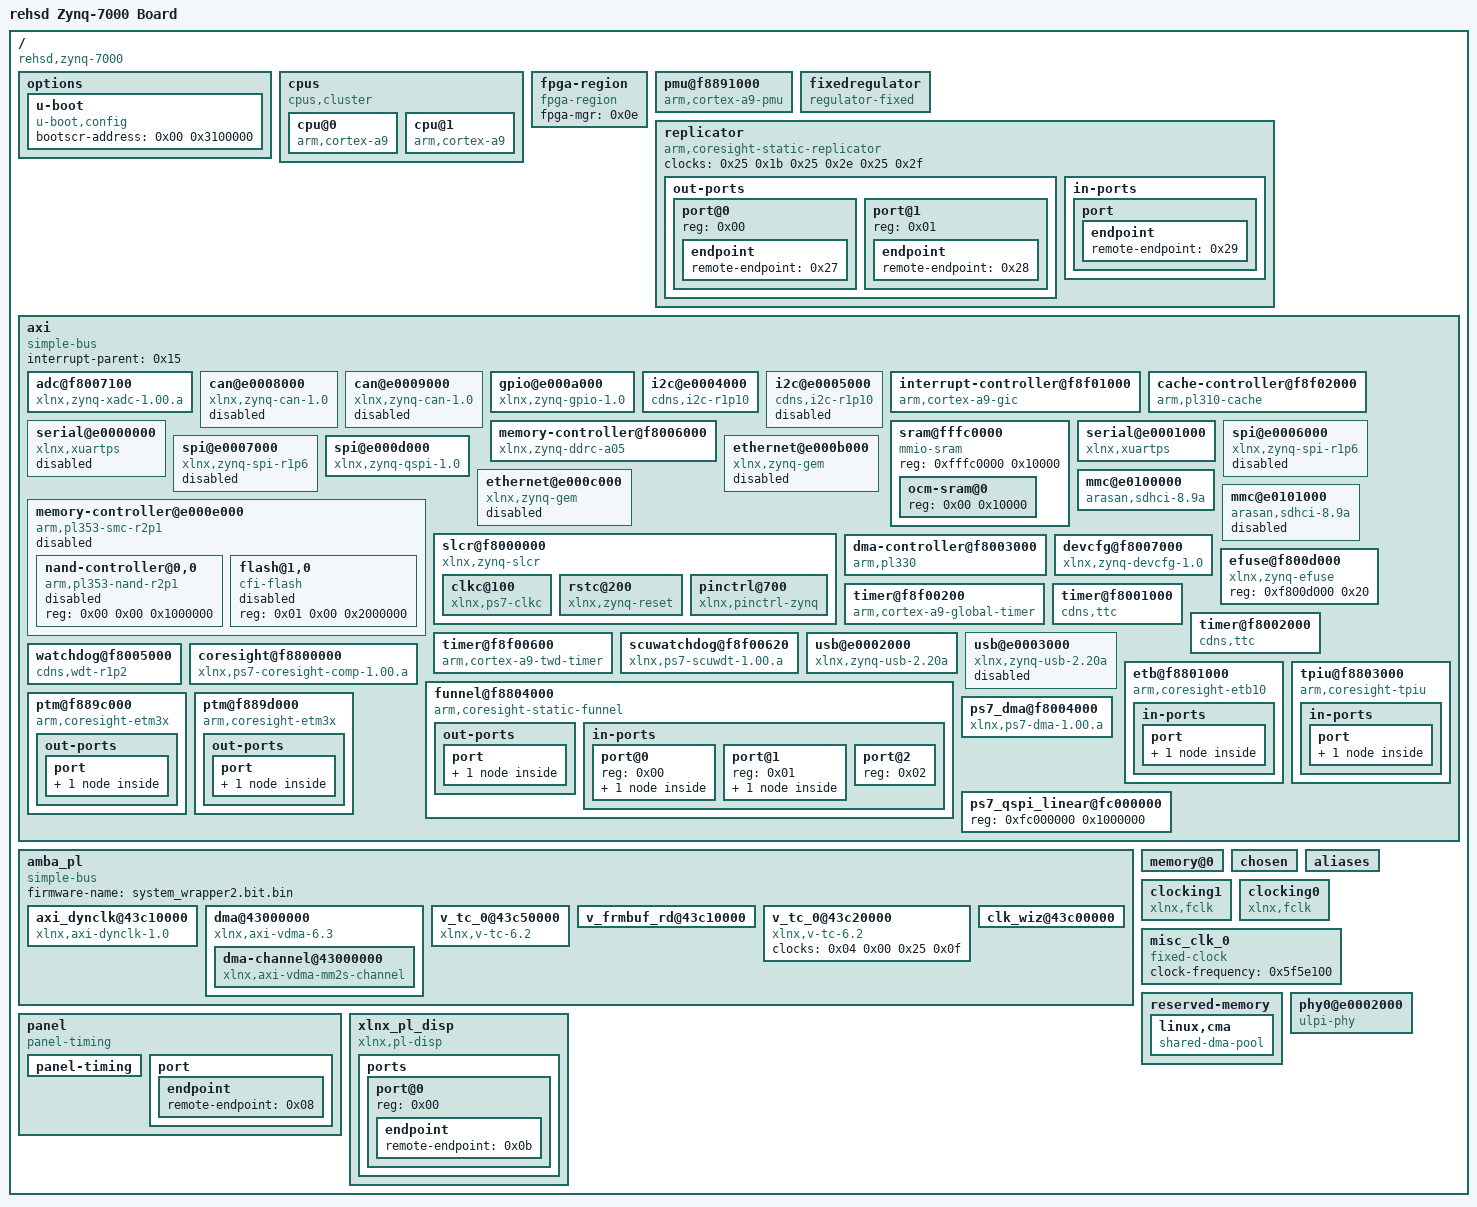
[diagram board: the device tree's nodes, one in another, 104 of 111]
/dts-v1/;

/ {
	#address-cells = <0x01>;
	#size-cells = <0x01>;
	compatible = "rehsd,zynq-7000\0xlnx,zynq-7000";
	model = "rehsd Zynq-7000 Board";
	device_id = "7z010";
	slrcount = <0x01>;
	family = "Zynq";
	speed_grade = "1";

	options {

		u-boot {
			compatible = "u-boot,config";
			bootscr-address = <0x00 0x3100000>;
		};
	};

	cpus {
		phandle = <0x34>;
		#address-cells = <0x01>;
		#size-cells = <0x00>;
		compatible = "cpus,cluster";
		#ranges-address-cells = <0x01>;
		#ranges-size-cells = <0x01>;

		cpu@0 {
			phandle = <0x2f>;
			compatible = "arm,cortex-a9";
			device_type = "cpu";
			reg = <0x00>;
			clocks = <0x25 0x03>;
			clock-latency = <0x3e8>;
			cpu0-supply = <0x26>;
			operating-points = <0xa2c2b 0xf4240 0x51616 0xf4240>;
			xlnx,i-cache-size = <0x8000>;
			xlnx,d-cache-line-size = <0x14>;
			xlnx,i-cache-line-size = <0x14>;
			xlnx,cpu-1x-clk-freq-hz = <0x69f6bcb>;
			xlnx,ip-name = "ps7_cortexa9";
			xlnx,d-cache-size = <0x8000>;
			xlnx,num-cores = <0x02>;
			xlnx,cpu-clk-freq-hz = <0x27bc86bf>;
			bus-handle = <0x01>;
		};

		cpu@1 {
			phandle = <0x31>;
			compatible = "arm,cortex-a9";
			device_type = "cpu";
			reg = <0x01>;
			clocks = <0x25 0x03>;
			xlnx,i-cache-size = <0x8000>;
			xlnx,d-cache-line-size = <0x14>;
			xlnx,i-cache-line-size = <0x14>;
			xlnx,cpu-1x-clk-freq-hz = <0x69f6bcb>;
			xlnx,ip-name = "ps7_cortexa9";
			xlnx,d-cache-size = <0x8000>;
			xlnx,cpu-clk-freq-hz = <0x27bc86bf>;
			bus-handle = <0x01>;
		};
	};

	fpga-region {
		phandle = <0x35>;
		compatible = "fpga-region";
		fpga-mgr = <0x0e>;
		#address-cells = <0x01>;
		#size-cells = <0x01>;
		ranges;
	};

	pmu@f8891000 {
		compatible = "arm,cortex-a9-pmu";
		interrupts = <0x00 0x05 0x04 0x00 0x06 0x04>;
		interrupt-parent = <0x15>;
		reg = <0xf8891000 0x1000 0xf8893000 0x1000>;
	};

	fixedregulator {
		phandle = <0x26>;
		compatible = "regulator-fixed";
		regulator-name = "VCCPINT";
		regulator-min-microvolt = <0xf4240>;
		regulator-max-microvolt = <0xf4240>;
		regulator-boot-on;
		regulator-always-on;
	};

	replicator {
		compatible = "arm,coresight-static-replicator";
		clocks = <0x25 0x1b 0x25 0x2e 0x25 0x2f>;
		clock-names = "apb_pclk\0dbg_trc\0dbg_apb";

		out-ports {
			#address-cells = <0x01>;
			#size-cells = <0x00>;

			port@0 {
				reg = <0x00>;

				endpoint {
					phandle = <0x2b>;
					remote-endpoint = <0x27>;
				};
			};

			port@1 {
				reg = <0x01>;

				endpoint {
					phandle = <0x2a>;
					remote-endpoint = <0x28>;
				};
			};
		};

		in-ports {

			port {

				endpoint {
					phandle = <0x2c>;
					remote-endpoint = <0x29>;
				};
			};
		};
	};

	axi {
		phandle = <0x01>;
		bootph-all;
		compatible = "simple-bus";
		#address-cells = <0x01>;
		#size-cells = <0x01>;
		interrupt-parent = <0x15>;
		ranges;

		adc@f8007100 {
			phandle = <0x24>;
			compatible = "xlnx,zynq-xadc-1.00.a";
			reg = <0xf8007100 0x20>;
			interrupts = <0x00 0x07 0x04>;
			interrupt-parent = <0x15>;
			clocks = <0x25 0x0c>;
			status = "okay";
			xlnx,ip-name = "ps7_xadc";
		};

		can@e0008000 {
			phandle = <0x36>;
			compatible = "xlnx,zynq-can-1.0";
			status = "disabled";
			clocks = <0x25 0x13 0x25 0x24>;
			clock-names = "can_clk\0pclk";
			reg = <0xe0008000 0x1000>;
			interrupts = <0x00 0x1c 0x04>;
			interrupt-parent = <0x15>;
			tx-fifo-depth = <0x40>;
			rx-fifo-depth = <0x40>;
		};

		can@e0009000 {
			phandle = <0x37>;
			compatible = "xlnx,zynq-can-1.0";
			status = "disabled";
			clocks = <0x25 0x14 0x25 0x25>;
			clock-names = "can_clk\0pclk";
			reg = <0xe0009000 0x1000>;
			interrupts = <0x00 0x33 0x04>;
			interrupt-parent = <0x15>;
			tx-fifo-depth = <0x40>;
			rx-fifo-depth = <0x40>;
		};

		gpio@e000a000 {
			phandle = <0x12>;
			compatible = "xlnx,zynq-gpio-1.0";
			#gpio-cells = <0x02>;
			clocks = <0x25 0x2a>;
			gpio-controller;
			interrupt-controller;
			#interrupt-cells = <0x02>;
			interrupt-parent = <0x15>;
			interrupts = <0x00 0x14 0x04>;
			reg = <0xe000a000 0x1000>;
			xlnx,mio-gpio-mask = <0x5600>;
			status = "okay";
			gpio-mask-high = <0x00>;
			xlnx,emio-gpio-width = <0x40>;
			xlnx,ip-name = "ps7_gpio";
			gpio-mask-low = <0x5600>;
			emio-gpio-width = <0x40>;
		};

		i2c@e0004000 {
			phandle = <0x14>;
			compatible = "cdns,i2c-r1p10";
			status = "okay";
			clocks = <0x25 0x26>;
			interrupt-parent = <0x15>;
			interrupts = <0x00 0x19 0x04>;
			clock-frequency = <0x61a80>;
			reg = <0xe0004000 0x1000>;
			#address-cells = <0x01>;
			#size-cells = <0x00>;
			xlnx,has-interrupt = <0x00>;
			xlnx,clock-freq = <0x69f6bcb>;
			xlnx,i2c-clk-freq-hz = <0x69f6bcb>;
			xlnx,ip-name = "ps7_i2c";
		};

		i2c@e0005000 {
			phandle = <0x38>;
			compatible = "cdns,i2c-r1p10";
			status = "disabled";
			clocks = <0x25 0x27>;
			interrupt-parent = <0x15>;
			interrupts = <0x00 0x30 0x04>;
			clock-frequency = <0x61a80>;
			reg = <0xe0005000 0x1000>;
			#address-cells = <0x01>;
			#size-cells = <0x00>;
		};

		interrupt-controller@f8f01000 {
			phandle = <0x15>;
			compatible = "arm,cortex-a9-gic";
			#interrupt-cells = <0x03>;
			interrupt-controller;
			reg = <0xf8f01000 0x1000 0xf8f00100 0x100>;
			status = "okay";
			xlnx,irq-f2p-mode = "DIRECT";
			xlnx,ip-name = "ps7_intc_dist";
		};

		cache-controller@f8f02000 {
			phandle = <0x17>;
			compatible = "arm,pl310-cache";
			reg = <0xf8f02000 0x1000>;
			interrupts = <0x00 0x02 0x04>;
			arm,data-latency = <0x03 0x02 0x02>;
			arm,tag-latency = <0x02 0x02 0x02>;
			cache-unified;
			cache-level = <0x02>;
			status = "okay";
			xlnx,ip-name = "ps7_pl310";
		};

		memory-controller@f8006000 {
			phandle = <0x0d>;
			compatible = "xlnx,zynq-ddrc-a05";
			reg = <0xf8006000 0x1000>;
			status = "okay";
			xlnx,ddr-clk-freq-hz = <0x1fca057e>;
			xlnx,ip-name = "ps7_ddrc";
			xlnx,has-ecc = <0x00>;
		};

		sram@fffc0000 {
			phandle = <0x39>;
			compatible = "mmio-sram";
			reg = <0xfffc0000 0x10000>;
			#address-cells = <0x01>;
			#size-cells = <0x01>;
			ranges = <0x00 0xfffc0000 0x10000>;

			ocm-sram@0 {
				reg = <0x00 0x10000>;
			};
		};

		serial@e0000000 {
			phandle = <0x3a>;
			compatible = "xlnx,xuartps\0cdns,uart-r1p8";
			status = "disabled";
			clocks = <0x25 0x17 0x25 0x28>;
			clock-names = "uart_clk\0pclk";
			reg = <0xe0000000 0x1000>;
			interrupts = <0x00 0x1b 0x04>;
			interrupt-parent = <0x15>;
		};

		serial@e0001000 {
			phandle = <0x22>;
			compatible = "xlnx,xuartps\0cdns,uart-r1p8";
			status = "okay";
			clocks = <0x25 0x18 0x25 0x29>;
			clock-names = "uart_clk\0pclk";
			reg = <0xe0001000 0x1000>;
			interrupts = <0x00 0x32 0x04>;
			interrupt-parent = <0x15>;
			xlnx,clock-freq = <0x5f5e100>;
			xlnx,has-modem = <0x00>;
			xlnx,ip-name = "ps7_uart";
			cts-override;
			port-number = <0x00>;
			xlnx,uart-clk-freq-hz = <0x5f5e100>;
		};

		spi@e0006000 {
			phandle = <0x3b>;
			compatible = "xlnx,zynq-spi-r1p6";
			reg = <0xe0006000 0x1000>;
			status = "disabled";
			interrupt-parent = <0x15>;
			interrupts = <0x00 0x1a 0x04>;
			clocks = <0x25 0x19 0x25 0x22>;
			clock-names = "ref_clk\0pclk";
			#address-cells = <0x01>;
			#size-cells = <0x00>;
		};

		spi@e0007000 {
			phandle = <0x3c>;
			compatible = "xlnx,zynq-spi-r1p6";
			reg = <0xe0007000 0x1000>;
			status = "disabled";
			interrupt-parent = <0x15>;
			interrupts = <0x00 0x31 0x04>;
			clocks = <0x25 0x1a 0x25 0x23>;
			clock-names = "ref_clk\0pclk";
			#address-cells = <0x01>;
			#size-cells = <0x00>;
		};

		spi@e000d000 {
			phandle = <0x1a>;
			compatible = "xlnx,zynq-qspi-1.0";
			reg = <0xe000d000 0x1000>;
			interrupt-parent = <0x15>;
			interrupts = <0x00 0x13 0x04>;
			clocks = <0x25 0x0a 0x25 0x2b>;
			clock-names = "ref_clk\0pclk";
			status = "okay";
			#address-cells = <0x01>;
			#size-cells = <0x00>;
			xlnx,qspi-fbclk = <0x00>;
			num-cs = <0x01>;
			xlnx,qspi-clk-freq-hz = <0xbebc200>;
			xlnx,bus-width = <0x02>;
			xlnx,ip-name = "ps7_qspi";
			spi-rx-bus-width = <0x04>;
			xlnx,connection-mode = <0x00>;
			spi-tx-bus-width = <0x04>;
			xlnx,clock-freq = <0xbebc200>;
			xlnx,fb-clk = <0x00>;
			xlnx,qspi-mode = <0x00>;
			xlnx,qspi-bus-width = <0x02>;
			is-dual = <0x00>;
		};

		ethernet@e000b000 {
			phandle = <0x3d>;
			compatible = "xlnx,zynq-gem\0cdns,gem";
			reg = <0xe000b000 0x1000>;
			status = "disabled";
			interrupts = <0x00 0x16 0x04>;
			interrupt-parent = <0x15>;
			clocks = <0x25 0x1e 0x25 0x1e 0x25 0x0d>;
			clock-names = "pclk\0hclk\0tx_clk";
			#address-cells = <0x01>;
			#size-cells = <0x00>;
		};

		ethernet@e000c000 {
			phandle = <0x3e>;
			compatible = "xlnx,zynq-gem\0cdns,gem";
			reg = <0xe000c000 0x1000>;
			status = "disabled";
			interrupts = <0x00 0x2d 0x04>;
			interrupt-parent = <0x15>;
			clocks = <0x25 0x1f 0x25 0x1f 0x25 0x0e>;
			clock-names = "pclk\0hclk\0tx_clk";
			#address-cells = <0x01>;
			#size-cells = <0x00>;
		};

		memory-controller@e000e000 {
			phandle = <0x3f>;
			compatible = "arm,pl353-smc-r2p1\0arm,primecell";
			reg = <0xe000e000 0x1000>;
			status = "disabled";
			clock-names = "memclk\0apb_pclk";
			clocks = <0x25 0x0b 0x25 0x2c>;
			ranges = <0x00 0x00 0xe1000000 0x1000000 0x01 0x00 0xe2000000 0x2000000 0x02 0x00 0xe4000000 0x2000000>;
			#address-cells = <0x02>;
			#size-cells = <0x01>;
			interrupt-parent = <0x15>;
			interrupts = <0x00 0x12 0x04>;

			nand-controller@0,0 {
				phandle = <0x40>;
				compatible = "arm,pl353-nand-r2p1";
				reg = <0x00 0x00 0x1000000>;
				status = "disabled";
			};

			flash@1,0 {
				phandle = <0x41>;
				status = "disabled";
				compatible = "cfi-flash";
				reg = <0x01 0x00 0x2000000>;
			};
		};

		mmc@e0100000 {
			phandle = <0x1f>;
			compatible = "arasan,sdhci-8.9a";
			status = "okay";
			clock-names = "clk_xin\0clk_ahb";
			clocks = <0x25 0x15 0x25 0x20>;
			interrupt-parent = <0x15>;
			interrupts = <0x00 0x18 0x04>;
			reg = <0xe0100000 0x1000>;
			xlnx,has-power = <0x00>;
			xlnx,ip-name = "ps7_sdio";
			xlnx,sdio-clk-freq-hz = <0x5f5e100>;
			xlnx,has-wp = <0x00>;
			xlnx,has-cd = <0x00>;
			u-boot,dm-pre-reloc;
		};

		mmc@e0101000 {
			phandle = <0x42>;
			compatible = "arasan,sdhci-8.9a";
			status = "disabled";
			clock-names = "clk_xin\0clk_ahb";
			clocks = <0x25 0x16 0x25 0x21>;
			interrupt-parent = <0x15>;
			interrupts = <0x00 0x2f 0x04>;
			reg = <0xe0101000 0x1000>;
		};

		slcr@f8000000 {
			phandle = <0x20>;
			bootph-all;
			#address-cells = <0x01>;
			#size-cells = <0x01>;
			compatible = "xlnx,zynq-slcr\0syscon\0simple-mfd";
			reg = <0xf8000000 0x1000>;
			ranges;
			status = "okay";
			xlnx,ip-name = "ps7_slcr";

			clkc@100 {
				phandle = <0x25>;
				bootph-all;
				#clock-cells = <0x01>;
				compatible = "xlnx,ps7-clkc";
				fclk-enable = <0x01>;
				clock-output-names = "armpll\0ddrpll\0iopll\0cpu_6or4x\0cpu_3or2x\0cpu_2x\0cpu_1x\0ddr2x\0ddr3x\0dci\0lqspi\0smc\0pcap\0gem0\0gem1\0fclk0\0fclk1\0fclk2\0fclk3\0can0\0can1\0sdio0\0sdio1\0uart0\0uart1\0spi0\0spi1\0dma\0usb0_aper\0usb1_aper\0gem0_aper\0gem1_aper\0sdio0_aper\0sdio1_aper\0spi0_aper\0spi1_aper\0can0_aper\0can1_aper\0i2c0_aper\0i2c1_aper\0uart0_aper\0uart1_aper\0gpio_aper\0lqspi_aper\0smc_aper\0swdt\0dbg_trc\0dbg_apb";
				reg = <0x100 0x100>;
				ps-clk-frequency = <0x1fca055>;
			};

			rstc@200 {
				phandle = <0x43>;
				compatible = "xlnx,zynq-reset";
				reg = <0x200 0x48>;
				#reset-cells = <0x01>;
				syscon = <0x20>;
			};

			pinctrl@700 {
				phandle = <0x44>;
				compatible = "xlnx,pinctrl-zynq";
				reg = <0x700 0x200>;
				syscon = <0x20>;
			};
		};

		dma-controller@f8003000 {
			phandle = <0x10>;
			compatible = "arm,pl330\0arm,primecell";
			reg = <0xf8003000 0x1000>;
			interrupt-parent = <0x15>;
			interrupts = <0x00 0x0d 0x04 0x00 0x0e 0x04 0x00 0x0f 0x04 0x00 0x10 0x04 0x00 0x11 0x04 0x00 0x28 0x04 0x00 0x29 0x04 0x00 0x2a 0x04 0x00 0x2b 0x04>;
			#dma-cells = <0x01>;
			clocks = <0x25 0x1b>;
			clock-names = "apb_pclk";
			status = "okay";
			xlnx,ip-name = "ps7_dma";
			xlnx,is-secure;
		};

		devcfg@f8007000 {
			phandle = <0x0e>;
			compatible = "xlnx,zynq-devcfg-1.0";
			reg = <0xf8007000 0x100>;
			interrupt-parent = <0x15>;
			interrupts = <0x00 0x08 0x04>;
			clocks = <0x25 0x0c 0x25 0x0f 0x25 0x10 0x25 0x11 0x25 0x12>;
			clock-names = "ref_clk\0fclk0\0fclk1\0fclk2\0fclk3";
			syscon = <0x20>;
			status = "okay";
			xlnx,ip-name = "ps7_dev_cfg";
		};

		efuse@f800d000 {
			phandle = <0x45>;
			compatible = "xlnx,zynq-efuse";
			reg = <0xf800d000 0x20>;
		};

		timer@f8f00200 {
			phandle = <0x11>;
			compatible = "arm,cortex-a9-global-timer";
			reg = <0xf8f00200 0x20>;
			interrupts = <0x01 0x0b 0x301>;
			interrupt-parent = <0x15>;
			clocks = <0x25 0x04>;
			status = "okay";
			xlnx,ip-name = "ps7_globaltimer";
		};

		timer@f8001000 {
			phandle = <0x21>;
			interrupt-parent = <0x15>;
			interrupts = <0x00 0x0a 0x04 0x00 0x0b 0x04 0x00 0x0c 0x04>;
			compatible = "cdns,ttc";
			clocks = <0x25 0x06>;
			reg = <0xf8001000 0x1000>;
			xlnx,ttc-clk2-freq-hz = <0x69f6bcb>;
			xlnx,ttc-clk1-clksrc = <0x00>;
			status = "okay";
			xlnx,clock-freq = <0x69f6bcb>;
			xlnx,ttc-clk2-clksrc = <0x00>;
			xlnx,ip-name = "ps7_ttc";
			xlnx,ttc-clk0-freq-hz = <0x69f6bcb>;
			xlnx,ttc-clk1-freq-hz = <0x69f6bcb>;
			xlnx,ttc-clk0-clksrc = <0x00>;
		};

		timer@f8002000 {
			phandle = <0x46>;
			interrupt-parent = <0x15>;
			interrupts = <0x00 0x25 0x04 0x00 0x26 0x04 0x00 0x27 0x04>;
			compatible = "cdns,ttc";
			clocks = <0x25 0x06>;
			reg = <0xf8002000 0x1000>;
		};

		timer@f8f00600 {
			phandle = <0x1d>;
			bootph-all;
			interrupt-parent = <0x15>;
			interrupts = <0x01 0x0d 0x301>;
			compatible = "arm,cortex-a9-twd-timer";
			reg = <0xf8f00600 0x20>;
			clocks = <0x25 0x04>;
			status = "okay";
			xlnx,ip-name = "ps7_scutimer";
		};

		scuwatchdog@f8f00620 {
			phandle = <0x1e>;
			interrupt-parent = <0x15>;
			interrupts = <0x01 0x0e 0x04>;
			compatible = "xlnx,ps7-scuwdt-1.00.a";
			reg = <0xf8f00620 0xe0>;
			status = "okay";
			xlnx,ip-name = "ps7_scuwdt";
		};

		usb@e0002000 {
			phandle = <0x23>;
			compatible = "xlnx,zynq-usb-2.20a\0chipidea,usb2";
			status = "okay";
			clocks = <0x25 0x1c>;
			interrupt-parent = <0x15>;
			interrupts = <0x00 0x15 0x04>;
			reg = <0xe0002000 0x1000>;
			phy_type = "ulpi";
			xlnx,ip-name = "ps7_usb";
			xlnx,enable-superspeed = <0x00>;
			dr_mode = "otg";
			usb-phy = <0x03>;
		};

		usb@e0003000 {
			phandle = <0x47>;
			compatible = "xlnx,zynq-usb-2.20a\0chipidea,usb2";
			status = "disabled";
			clocks = <0x25 0x1d>;
			interrupt-parent = <0x15>;
			interrupts = <0x00 0x2c 0x04>;
			reg = <0xe0003000 0x1000>;
			phy_type = "ulpi";
		};

		watchdog@f8005000 {
			phandle = <0x48>;
			clocks = <0x25 0x2d>;
			compatible = "cdns,wdt-r1p2";
			interrupt-parent = <0x15>;
			interrupts = <0x00 0x09 0x01>;
			reg = <0xf8005000 0x1000>;
			timeout-sec = <0x0a>;
		};

		coresight@f8800000 {
			phandle = <0x0c>;
			compatible = "xlnx,ps7-coresight-comp-1.00.a";
			status = "okay";
			reg = <0xf8800000 0x100000>;
			xlnx,ip-name = "ps7_coresight_comp";
		};

		etb@f8801000 {
			compatible = "arm,coresight-etb10\0arm,primecell";
			reg = <0xf8801000 0x1000>;
			clocks = <0x25 0x1b 0x25 0x2e 0x25 0x2f>;
			clock-names = "apb_pclk\0dbg_trc\0dbg_apb";

			in-ports {

				port {

					endpoint {
						phandle = <0x28>;
						remote-endpoint = <0x2a>;
					};
				};
			};
		};

		tpiu@f8803000 {
			compatible = "arm,coresight-tpiu\0arm,primecell";
			reg = <0xf8803000 0x1000>;
			clocks = <0x25 0x1b 0x25 0x2e 0x25 0x2f>;
			clock-names = "apb_pclk\0dbg_trc\0dbg_apb";

			in-ports {

				port {

					endpoint {
						phandle = <0x27>;
						remote-endpoint = <0x2b>;
					};
				};
			};
		};

		funnel@f8804000 {
			compatible = "arm,coresight-static-funnel\0arm,primecell";
			reg = <0xf8804000 0x1000>;
			clocks = <0x25 0x1b 0x25 0x2e 0x25 0x2f>;
			clock-names = "apb_pclk\0dbg_trc\0dbg_apb";

			out-ports {

				port {

					endpoint {
						phandle = <0x29>;
						remote-endpoint = <0x2c>;
					};
				};
			};

			in-ports {
				#address-cells = <0x01>;
				#size-cells = <0x00>;

				port@0 {
					reg = <0x00>;

					endpoint {
						phandle = <0x30>;
						remote-endpoint = <0x2d>;
					};
				};

				port@1 {
					reg = <0x01>;

					endpoint {
						phandle = <0x32>;
						remote-endpoint = <0x2e>;
					};
				};

				port@2 {
					reg = <0x02>;
				};
			};
		};

		ptm@f889c000 {
			compatible = "arm,coresight-etm3x\0arm,primecell";
			reg = <0xf889c000 0x1000>;
			clocks = <0x25 0x1b 0x25 0x2e 0x25 0x2f>;
			clock-names = "apb_pclk\0dbg_trc\0dbg_apb";
			cpu = <0x2f>;

			out-ports {

				port {

					endpoint {
						phandle = <0x2d>;
						remote-endpoint = <0x30>;
					};
				};
			};
		};

		ptm@f889d000 {
			compatible = "arm,coresight-etm3x\0arm,primecell";
			reg = <0xf889d000 0x1000>;
			clocks = <0x25 0x1b 0x25 0x2e 0x25 0x2f>;
			clock-names = "apb_pclk\0dbg_trc\0dbg_apb";
			cpu = <0x31>;

			out-ports {

				port {

					endpoint {
						phandle = <0x2e>;
						remote-endpoint = <0x32>;
					};
				};
			};
		};

		ps7_dma@f8004000 {
			phandle = <0x0f>;
			compatible = "xlnx,ps7-dma-1.00.a";
			status = "okay";
			xlnx,ip-name = "ps7_dma";
			xlnx,is-secure;
			reg = <0xf8004000 0x1000>;
		};

		ps7_qspi_linear@fc000000 {
			phandle = <0x4e>;
			reg = <0xfc000000 0x1000000>;
		};
	};

	amba_pl {
		phandle = <0x4f>;
		ranges;
		compatible = "simple-bus";
		#address-cells = <0x01>;
		#size-cells = <0x01>;
		firmware-name = "system_wrapper2.bit.bin";

		axi_dynclk@43c10000 {
			phandle = <0x06>;
			xlnx,s00-axi-data-width = <0x20>;
			compatible = "xlnx,axi-dynclk-1.0";
			status = "okay";
			clock-names = "REF_CLK_I\0s00_axi_aclk";
			xlnx,s00-axi-addr-width = <0x05>;
			xlnx,ip-name = "axi_dynclk";
			xlnx,edk-iptype = "PERIPHERAL";
			reg = <0x43c10000 0x10000>;
			clocks = <0x25 0x0f 0x25 0x0f>;
		};

		dma@43000000 {
			phandle = <0x05>;
			xlnx,enable-debug-info-9 = <0x00>;
			xlnx,enable-s2mm-frm-counter = <0x01>;
			xlnx,enable-mm2s-delay-counter = <0x01>;
			xlnx,dlytmr-resolution = <0x7d>;
			xlnx,enable-s2mm-buf-full = <0x00>;
			xlnx,ip-name = "axi_vdma";
			xlnx,s2mm-genlock-num-masters = <0x01>;
			reg = <0x43000000 0x10000>;
			xlnx,enable-s2mm-fsync-out = <0x00>;
			xlnx,use-mm2s-fsync = <0x00>;
			xlnx,s2mm-linebuffer-thresh = <0x04>;
			xlnx,enable-mm2s-frm-counter = <0x01>;
			xlnx,m-axis-mm2s-tdata-width = <0x20>;
			xlnx,enable-all = <0x00>;
			xlnx,dynamic-resolution = <0x01>;
			xlnx,enable-s2mm-rst-out = <0x00>;
			interrupt-names = "mm2s_introut";
			xlnx,s2mm-sof-enable = <0x01>;
			xlnx,mm2s-genlock-num-masters = <0x01>;
			xlnx,enable-mm2s-fsync-out = <0x00>;
			xlnx,mm2s-linebuffer-thresh = <0x04>;
			compatible = "xlnx,axi-vdma-6.3\0xlnx,axi-vdma-1.00.a";
			xlnx,enable-tstvec = <0x00>;
			interrupt-parent = <0x15>;
			xlnx,s2mm-max-burst-length = <0x08>;
			xlnx,enable-mm2s-rst-out = <0x00>;
			xlnx,mm2s-sof-enable = <0x01>;
			xlnx,include-s2mm-dre = <0x00>;
			xlnx,enable-s2mm-frmstr-reg = <0x00>;
			xlnx,m-axi-s2mm-data-width = <0x40>;
			xlnx,enable-s2mm-sts-reg = <0x00>;
			xlnx,mm2s-max-burst-length = <0x08>;
			status = "okay";
			xlnx,include-mm2s-dre = <0x00>;
			xlnx,enable-mm2s-frmstr-reg = <0x00>;
			interrupts = <0x00 0x1d 0x04>;
			xlnx,m-axi-mm2s-data-width = <0x40>;
			xlnx,flush-on-fsync = <0x01>;
			xlnx,include-s2mm-sf = <0x01>;
			xlnx,single-interface = <0x00>;
			xlnx,s2mm-linebuffer-depth = <0x200>;
			xlnx,include-s2mm = <0x00>;
			xlnx,addr-width = <0x20>;
			clocks = <0x25 0x0f 0x25 0x0f 0x25 0x0f>;
			xlnx,s-axis-s2mm-tdata-width = <0x20>;
			xlnx,enable-debug-info-10 = <0x00>;
			xlnx,addrwidth = <0x20>;
			xlnx,enable-debug-info-11 = <0x00>;
			xlnx,edk-iptype = "PERIPHERAL";
			xlnx,enable-debug-info-12 = <0x00>;
			xlnx,use-fsync = <0x01>;
			xlnx,s2mm-genlock-repeat-en = <0x01>;
			xlnx,enable-debug-info-13 = <0x00>;
			xlnx,enable-vert-flip = <0x00>;
			xlnx,include-mm2s-sf = <0x00>;
			xlnx,enable-debug-info-14 = <0x01>;
			xlnx,include-internal-genlock = <0x01>;
			clock-names = "m_axi_mm2s_aclk\0m_axis_mm2s_aclk\0s_axi_lite_aclk";
			xlnx,enable-debug-info-15 = <0x01>;
			xlnx,mm2s-linebuffer-depth = <0x200>;
			xlnx,include-mm2s = <0x01>;
			xlnx,s2mm-genlock-mode = <0x00>;
			xlnx,flush-fsync = <0x01>;
			xlnx,select-xpm = <0x00>;
			xlnx,s2mm-data-width = <0x40>;
			xlnx,num-fstores = <0x04>;
			xlnx,enable-s2mm-param-updt = <0x00>;
			xlnx,enable-vidparam-reads = <0x01>;
			xlnx,mm2s-genlock-repeat-en = <0x00>;
			xlnx,prmry-is-aclk-async = <0x00>;
			xlnx,s2mm-tdata-width = <0x20>;
			#dma-cells = <0x01>;
			xlnx,enable-vidprmtr-reads = <0x01>;
			xlnx,mm2s-genlock-mode = <0x03>;
			xlnx,enable-debug-info-0 = <0x00>;
			xlnx,enable-debug-all = <0x00>;
			xlnx,enable-debug-info-1 = <0x00>;
			xlnx,mm2s-data-width = <0x40>;
			xlnx,enable-debug-info-2 = <0x00>;
			xlnx,enable-mm2s-param-updt = <0x00>;
			xlnx,enable-debug-info-3 = <0x00>;
			xlnx,enable-s2mm-delay-counter = <0x01>;
			xlnx,enable-debug-info-4 = <0x00>;
			xlnx,enable-debug-info-5 = <0x00>;
			xlnx,mm2s-tdata-width = <0x20>;
			xlnx,enable-debug-info-6 = <0x01>;
			xlnx,enable-debug-info-7 = <0x01>;
			xlnx,use-s2mm-fsync = <0x02>;
			xlnx,enable-debug-info-8 = <0x00>;
			xlnx,enable-mm2s-buf-empty = <0x00>;

			dma-channel@43000000 {
				phandle = <0x53>;
				interrupts = <0x00 0x1d 0x04>;
				xlnx,datawidth = <0x20>;
				xlnx,device-id = <0x00>;
				compatible = "xlnx,axi-vdma-mm2s-channel";
				xlnx,genlock-mode;
			};
		};

		v_tc_0@43c50000 {
			phandle = <0x07>;
			xlnx,gen-vsync-en = <0x01>;
			xlnx,gen-hframe-size = <0x672>;
			xlnx,num-fsyncs = <0x01>;
			xlnx,gen-hactive-size = <0x500>;
			xlnx,gen-video-format = <0x02>;
			xlnx,gen-f1-vblank-hstart = <0x56e>;
			xlnx,active-video-detection;
			xlnx,horizontal-sync-generation;
			xlnx,gen-vblank-en = <0x01>;
			xlnx,gen-avideo-en = <0x01>;
			xlnx,ip-name = "v_tc";
			xlnx,fsync-hstart10 = <0x00>;
			xlnx,max-pixels = <0x1000>;
			xlnx,gen-fieldid-en = <0x00>;
			reg = <0x43c50000 0x10000>;
			xlnx,det-vblank-en = <0x01>;
			xlnx,fsync-hstart11 = <0x00>;
			xlnx,fsync-hstart12 = <0x00>;
			xlnx,pixels-per-clock = <0x04>;
			xlnx,gen-interlaced = <0x00>;
			xlnx,det-avideo-en = <0x01>;
			xlnx,fsync-hstart13 = <0x00>;
			xlnx,fsync-hstart14 = <0x00>;
			xlnx,gen-f0-vblank-hend = <0x56e>;
			xlnx,fsync-hstart15 = <0x00>;
			xlnx,det-hsync-en = <0x01>;
			interrupt-names = "irq";
			xlnx,enable-generation;
			xlnx,gen-avideo-polarity = <0x01>;
			xlnx,max-lines-per-frame = <0x1000>;
			xlnx,has-axi4-lite = <0x01>;
			compatible = "xlnx,v-tc-6.2\0xlnx,bridge-v-tc-6.1";
			xlnx,max-clocks-per-line = <0x1000>;
			xlnx,gen-f0-vframe-size = <0x2ee>;
			xlnx,gen-f0-vblank-hstart = <0x56e>;
			interrupt-parent = <0x15>;
			xlnx,max-lines = <0x1000>;
			xlnx,gen-f0-vsync-vstart = <0x2d4>;
			xlnx,horizontal-blank-generation;
			xlnx,gen-hsync-end = <0x596>;
			xlnx,gen-f0-vsync-hstart = <0x56e>;
			xlnx,gen-f1-vsync-hend = <0x56e>;
			xlnx,vertical-blank-detection;
			xlnx,gen-vsync-polarity = <0x01>;
			xlnx,fsync-vstart0 = <0x00>;
			xlnx,gen-hsync-polarity = <0x01>;
			xlnx,fsync-vstart1 = <0x00>;
			status = "okay";
			xlnx,fsync-vstart2 = <0x00>;
			xlnx,gen-hsync-start = <0x56e>;
			xlnx,gen-f0-vsync-vend = <0x2d9>;
			xlnx,fsync-vstart3 = <0x00>;
			xlnx,vertical-sync-detection;
			xlnx,frame-syncs = <0x01>;
			xlnx,fsync-vstart4 = <0x00>;
			xlnx,gen-vactive-size = <0x2d0>;
			xlnx,fsync-vstart5 = <0x00>;
			interrupts = <0x00 0x1e 0x04>;
			xlnx,gen-achroma-en = <0x00>;
			xlnx,fsync-vstart6 = <0x00>;
			xlnx,det-fieldid-en = <0x00>;
			xlnx,fsync-vstart7 = <0x00>;
			xlnx,gen-hsync-en = <0x01>;
			xlnx,fsync-vstart8 = <0x00>;
			xlnx,fsync-vstart10 = <0x00>;
			xlnx,fsync-vstart9 = <0x00>;
			xlnx,fsync-vstart11 = <0x00>;
			xlnx,arbitrary-res-en = [00];
			xlnx,fsync-vstart12 = <0x00>;
			xlnx,fsync-vstart13 = <0x00>;
			clocks = <0x33 0x25 0x0f>;
			xlnx,fsync-vstart14 = <0x00>;
			xlnx,fsync-vstart15 = <0x00>;
			xlnx,gen-cparity = <0x00>;
			xlnx,edk-iptype = "PERIPHERAL";
			xlnx,vertical-sync-generation;
			xlnx,gen-f1-vblank-hend = <0x56e>;
			xlnx,det-vsync-en = <0x01>;
			xlnx,gen-vblank-polarity = <0x01>;
			xlnx,fsync-hstart0 = <0x00>;
			clock-names = "clk\0s_axi_aclk";
			xlnx,interlace-en = <0x00>;
			xlnx,gen-auto-switch = <0x00>;
			xlnx,fsync-hstart1 = <0x00>;
			xlnx,fsync-hstart2 = <0x00>;
			xlnx,active-video-generation;
			xlnx,fsync-hstart3 = <0x00>;
			xlnx,fsync-hstart4 = <0x00>;
			xlnx,horizontal-blank-detection;
			xlnx,fsync-hstart5 = <0x00>;
			xlnx,gen-f1-vframe-size = <0x2ee>;
			xlnx,fsync-hstart6 = <0x00>;
			xlnx,fsync-hstart7 = <0x00>;
			xlnx,fsync-hstart8 = <0x00>;
			xlnx,gen-hblank-en = <0x01>;
			xlnx,fsync-hstart9 = <0x00>;
			xlnx,horizontal-sync-detection;
			xlnx,gen-f1-vsync-vend = <0x2d9>;
			xlnx,detect-en = <0x00>;
			xlnx,det-hblank-en = <0x01>;
			xlnx,vid-ppc = <0x04>;
			xlnx,has-intc-if = <0x00>;
			xlnx,generate-en = <0x01>;
			xlnx,gen-achroma-polarity = <0x01>;
			xlnx,sync-en = <0x00>;
			xlnx,det-achroma-en = <0x00>;
			xlnx,generator;
			xlnx,gen-f1-vsync-vstart = <0x2d4>;
			xlnx,vertical-blank-generation;
			xlnx,gen-hblank-polarity = <0x01>;
			xlnx,video-mode = "720p";
			xlnx,gen-fieldid-polarity = <0x01>;
			xlnx,gen-f1-vsync-hstart = <0x56e>;
			xlnx,gen-f0-vsync-hend = <0x56e>;
		};

		v_frmbuf_rd@43c10000 {
			status = "okay";
			#dma-cells = <0x01>;
			phandle = <0x09>;
		};

		v_tc_0@43c20000 {
			status = "okay";
			compatible = "xlnx,v-tc-6.2\0xlnx,bridge-v-tc-6.1";
			clocks = <0x04 0x00 0x25 0x0f>;
			clock-names = "clk\0s_axi_aclk";
			phandle = <0x0a>;
		};

		clk_wiz@43c00000 {
			status = "okay";
			#clock-cells = <0x01>;
			phandle = <0x04>;
		};
	};

	memory@0 {
		phandle = <0x02>;
		xlnx,ip-name = "ps7_ddr";
		device_type = "memory";
		memory_type = "memory";
		reg = <0x00 0x20000000>;
	};

	chosen {
		stdout-path = "serial0:115200n8";
		bootargs = "console=ttyPS0,115200 earlyprintk root=/dev/mmcblk0p2 rw rootwait uio_pdrv_genirq.of_id=generic-uio cma=128M video=HDMI-A-1:1280x720-32@60,e";
	};

	aliases {
		serial0 = "/axi/serial@e0001000";
		spi0 = "/axi/spi@e000d000";
		serial1 = "/axi/coresight@f8800000";
		i2c0 = "/axi/i2c@e0004000";
	};

	__symbols__ {
		cpus_a9 = "/cpus-a9@0";
		ps7_cortexa9_0 = "/cpus-a9@0/cpu@0";
		ps7_cortexa9_1 = "/cpus-a9@0/cpu@1";
		fpga_full = "/fpga-region";
		regulator_vccpint = "/fixedregulator";
		replicator_out_port0 = "/replicator/out-ports/port@0/endpoint";
		replicator_out_port1 = "/replicator/out-ports/port@1/endpoint";
		replicator_in_port0 = "/replicator/in-ports/port/endpoint";
		amba = "/axi";
		adc = "/axi/adc@f8007100";
		can0 = "/axi/can@e0008000";
		can1 = "/axi/can@e0009000";
		gpio0 = "/axi/gpio@e000a000";
		i2c0 = "/axi/i2c@e0004000";
		i2c1 = "/axi/i2c@e0005000";
		intc = "/axi/interrupt-controller@f8f01000";
		L2 = "/axi/cache-controller@f8f02000";
		mc = "/axi/memory-controller@f8006000";
		ocm = "/axi/sram@fffc0000";
		uart0 = "/axi/serial@e0000000";
		uart1 = "/axi/serial@e0001000";
		spi0 = "/axi/spi@e0006000";
		spi1 = "/axi/spi@e0007000";
		qspi = "/axi/spi@e000d000";
		gem0 = "/axi/ethernet@e000b000";
		gem1 = "/axi/ethernet@e000c000";
		smcc = "/axi/memory-controller@e000e000";
		nfc0 = "/axi/memory-controller@e000e000/nand-controller@0,0";
		nor0 = "/axi/memory-controller@e000e000/flash@1,0";
		sdhci0 = "/axi/mmc@e0100000";
		sdhci1 = "/axi/mmc@e0101000";
		slcr = "/axi/slcr@f8000000";
		clkc = "/axi/slcr@f8000000/clkc@100";
		rstc = "/axi/slcr@f8000000/rstc@200";
		pinctrl0 = "/axi/slcr@f8000000/pinctrl@700";
		dmac_s = "/axi/dma-controller@f8003000";
		devcfg = "/axi/devcfg@f8007000";
		efuse = "/axi/efuse@f800d000";
		global_timer = "/axi/timer@f8f00200";
		ttc0 = "/axi/timer@f8001000";
		ttc1 = "/axi/timer@f8002000";
		scutimer = "/axi/timer@f8f00600";
		scuwdt = "/axi/scuwatchdog@f8f00620";
		usb0 = "/axi/usb@e0002000";
		usb1 = "/axi/usb@e0003000";
		watchdog0 = "/axi/watchdog@f8005000";
		coresight = "/axi/coresight@f8800000";
		etb_in_port = "/axi/etb@f8801000/in-ports/port/endpoint";
		tpiu_in_port = "/axi/tpiu@f8803000/in-ports/port/endpoint";
		funnel_out_port = "/axi/funnel@f8804000/out-ports/port/endpoint";
		funnel0_in_port0 = "/axi/funnel@f8804000/in-ports/port@0/endpoint";
		funnel0_in_port1 = "/axi/funnel@f8804000/in-ports/port@1/endpoint";
		ptm0_out_port = "/axi/ptm@f889c000/out-ports/port/endpoint";
		ptm1_out_port = "/axi/ptm@f889d000/out-ports/port/endpoint";
		ps7_dma_ns = "/axi/ps7_dma@f8004000";
		ps7_qspi_linear_0 = "/axi/ps7_qspi_linear@fc000000";
		amba_pl = "/amba_pl";
		axi_dynclk_0 = "/amba_pl/axi_dynclk@43c10000";
		axi_vdma_0 = "/amba_pl/dma@43000000";
		dma_channel_43000000 = "/amba_pl/dma@43000000/dma-channel@43000000";
		v_tc_0 = "/amba_pl/v_tc_0@43c50000";
		ps7_ddr_0_memory = "/memory@00100000";
		DISP_DMA = "/amba_pl/v_frmbuf_rd@43c10000";
		DISP_VTC = "/amba_pl/v_tc_0@43c20000";
		DISP_CLK = "/amba_pl/clk_wiz@43c00000";
		clocking1 = "/clocking1";
		clocking0 = "/clocking0";
		misc_clk_0 = "/misc_clk_0";
		usb_phy0 = "/phy0@e0002000";
		fixed_panel = "/panel";
		panel_in = "/panel/port/endpoint";
		xlnx_pl_disp = "/xlnx_pl_disp";
		pl_disp_ep = "/xlnx_pl_disp/ports/port@0/endpoint";
	};

	clocking1 {
		phandle = <0x50>;
		compatible = "xlnx,fclk";
		assigned-clocks = <0x25 0x10>;
		assigned-clock-rates = <0xbebc200>;
		#clock-cells = <0x00>;
		clock-output-names = "fabric_clk";
		clocks = <0x25 0x10>;
	};

	clocking0 {
		phandle = <0x51>;
		compatible = "xlnx,fclk";
		assigned-clocks = <0x25 0x0f>;
		assigned-clock-rates = <0x5f5e100>;
		#clock-cells = <0x00>;
		clock-output-names = "fabric_clk";
		clocks = <0x25 0x0f>;
	};

	misc_clk_0 {
		phandle = <0x33>;
		compatible = "fixed-clock";
		clock-frequency = <0x5f5e100>;
		#clock-cells = <0x00>;
	};

	reserved-memory {
		#address-cells = <0x01>;
		#size-cells = <0x01>;
		ranges;

		linux,cma {
			compatible = "shared-dma-pool";
			reusable;
			size = <0x8000000>;
			linux,cma-default;
		};
	};

	phy0@e0002000 {
		compatible = "ulpi-phy";
		#phy-cells = <0x00>;
		reg = <0xe0002000 0x1000>;
		view-port = <0x170>;
		drv-vbus;
		phandle = <0x03>;
	};

	panel {
		compatible = "panel-timing";
		phandle = <0x13>;

		panel-timing {
			clock-frequency = <0x46cf710>;
			hactive = <0x500>;
			vactive = <0x2d0>;
			hfront-porch = <0x6e>;
			hsync-len = <0x28>;
			hback-porch = <0xdc>;
			vfront-porch = <0x05>;
			vsync-len = <0x05>;
			vback-porch = <0x14>;
			hsync-active = <0x00>;
			vsync-active = <0x00>;
		};

		port {

			endpoint {
				remote-endpoint = <0x08>;
				phandle = <0x0b>;
			};
		};
	};

	xlnx_pl_disp {
		compatible = "xlnx,pl-disp";
		dmas = <0x09 0x00>;
		dma-names = "dma0";
		xlnx,vformat = "AR24";
		xlnx,bridge = <0x0a>;
		phandle = <0x16>;

		ports {
			#address-cells = <0x01>;
			#size-cells = <0x00>;

			port@0 {
				reg = <0x00>;

				endpoint {
					remote-endpoint = <0x0b>;
					phandle = <0x08>;
				};
			};
		};
	};
};
